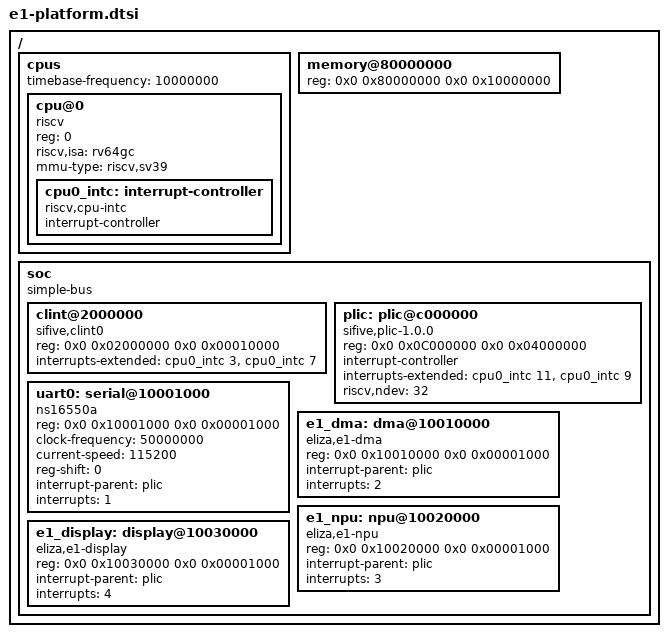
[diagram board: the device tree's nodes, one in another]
// SPDX-License-Identifier: GPL-2.0-only OR BSD-2-Clause
// Generated by scripts/gen_platform_artifacts.py from sw/platform/e1_platform_contract.json. DO NOT EDIT BY HAND.
/ {
	#address-cells = <2>;
	#size-cells = <2>;

	cpus {
		#address-cells = <1>;
		#size-cells = <0>;
		timebase-frequency = <10000000>;
		cpu@0 {
			device_type = "cpu";
			reg = <0>;
			status = "okay";
			compatible = "riscv";
			riscv,isa = "rv64gc";
			mmu-type = "riscv,sv39";
			cpu0_intc: interrupt-controller {
				#interrupt-cells = <1>;
				interrupt-controller;
				compatible = "riscv,cpu-intc";
			};
		};
	};

	memory@80000000 {
		device_type = "memory";
		reg = <0x0 0x80000000 0x0 0x10000000>;
	};

	soc {
		compatible = "simple-bus";
		#address-cells = <2>;
		#size-cells = <2>;
		ranges;

		clint@2000000 {
			compatible = "sifive,clint0", "riscv,clint0";
			reg = <0x0 0x02000000 0x0 0x00010000>;
			interrupts-extended = <&cpu0_intc 3>, <&cpu0_intc 7>;
		};

		plic: plic@c000000 {
			compatible = "sifive,plic-1.0.0", "riscv,plic0";
			reg = <0x0 0x0C000000 0x0 0x04000000>;
			#interrupt-cells = <1>;
			interrupt-controller;
			interrupts-extended = <&cpu0_intc 11>, <&cpu0_intc 9>;
			riscv,ndev = <32>;
		};

		uart0: serial@10001000 {
			compatible = "ns16550a";
			reg = <0x0 0x10001000 0x0 0x00001000>;
			clock-frequency = <50000000>;
			current-speed = <115200>;
			reg-shift = <0>;
			interrupt-parent = <&plic>;
			interrupts = <1>;
		};

		e1_dma: dma@10010000 {
			compatible = "eliza,e1-dma";
			reg = <0x0 0x10010000 0x0 0x00001000>;
			interrupt-parent = <&plic>;
			interrupts = <2>;
		};

		e1_npu: npu@10020000 {
			compatible = "eliza,e1-npu";
			reg = <0x0 0x10020000 0x0 0x00001000>;
			interrupt-parent = <&plic>;
			interrupts = <3>;
		};

		e1_display: display@10030000 {
			compatible = "eliza,e1-display";
			reg = <0x0 0x10030000 0x0 0x00001000>;
			interrupt-parent = <&plic>;
			interrupts = <4>;
		};

	};
};
